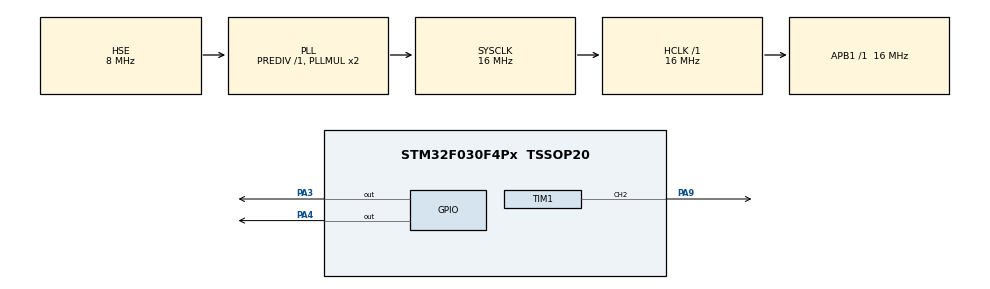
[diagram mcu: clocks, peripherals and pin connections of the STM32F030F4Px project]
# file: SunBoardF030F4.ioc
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Mcu.Family=STM32F0
Mcu.Name=STM32F030F4Px
Mcu.Package=TSSOP20
PA13.Mode=Serial_Wire
PA13.Signal=SYS_SWDIO
PA14.Mode=Serial_Wire
PA14.Signal=SYS_SWCLK
PA3.Signal=GPIO_Output
PA4.Signal=GPIO_Output
PA9.Signal=S_TIM1_CH2
PF0-OSC_IN.Mode=HSE-External-Oscillator
PF0-OSC_IN.Signal=RCC_OSC_IN
PF1-OSC_OUT.Mode=HSE-External-Oscillator
PF1-OSC_OUT.Signal=RCC_OSC_OUT
ProjectManager.HeapSize=0x200
ProjectManager.StackSize=0x400
ProjectManager.TargetToolchain=TrueSTUDIO
RCC.AHBFreq_Value=16000000
RCC.APB1Freq_Value=16000000
RCC.APB1TimFreq_Value=16000000
RCC.HCLKFreq_Value=16000000
RCC.PLLSourceVirtual=RCC_PLLSOURCE_HSE
RCC.RTCClockSelection=RCC_RTCCLKSOURCE_HSE_DIV32
RCC.SYSCLKFreq_VALUE=16000000
RCC.SYSCLKSource=RCC_SYSCLKSOURCE_PLLCLK
RTC.Format=RTC_FORMAT_BIN
RTC.Hours=12
RTC.Minutes=12
RTC.Seconds=12
RTC.SynchPrediv=1999
SH.S_TIM1_CH2.0=TIM1_CH2,PWM Generation2 CH2
TIM1.Channel-PWM\ Generation2\ CH2=TIM_CHANNEL_2
VP_RTC_VS_RTC_Activate.Mode=RTC_Enabled
VP_RTC_VS_RTC_Calendar.Mode=RTC_Calendar
board=custom

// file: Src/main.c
/* USER CODE BEGIN Header */
/**
  ******************************************************************************
  * @file           : main.c
  * @brief          : Main program body
  ******************************************************************************
  ** This notice applies to any and all portions of this file
  * that are not between comment pairs USER CODE BEGIN and
  * USER CODE END. Other portions of this file, whether
  * inserted by the user or by software development tools
  * are owned by their respective copyright owners.
  *
  * COPYRIGHT(c) 2019 STMicroelectronics
  *
  * Redistribution and use in source and binary forms, with or without modification,
  * are permitted provided that the following conditions are met:
  *   1. Redistributions of source code must retain the above copyright notice,
  *      this list of conditions and the following disclaimer.
  *   2. Redistributions in binary form must reproduce the above copyright notice,
  *      this list of conditions and the following disclaimer in the documentation
  *      and/or other materials provided with the distribution.
  *   3. Neither the name of STMicroelectronics nor the names of its contributors
  *      may be used to endorse or promote products derived from this software
  *      without specific prior written permission.
  *
  * THIS SOFTWARE IS PROVIDED BY THE COPYRIGHT HOLDERS AND CONTRIBUTORS "AS IS"
  * AND ANY EXPRESS OR IMPLIED WARRANTIES, INCLUDING, BUT NOT LIMITED TO, THE
  * IMPLIED WARRANTIES OF MERCHANTABILITY AND FITNESS FOR A PARTICULAR PURPOSE ARE
  * DISCLAIMED. IN NO EVENT SHALL THE COPYRIGHT HOLDER OR CONTRIBUTORS BE LIABLE
  * FOR ANY DIRECT, INDIRECT, INCIDENTAL, SPECIAL, EXEMPLARY, OR CONSEQUENTIAL
  * DAMAGES (INCLUDING, BUT NOT LIMITED TO, PROCUREMENT OF SUBSTITUTE GOODS OR
  * SERVICES; LOSS OF USE, DATA, OR PROFITS; OR BUSINESS INTERRUPTION) HOWEVER
  * CAUSED AND ON ANY THEORY OF LIABILITY, WHETHER IN CONTRACT, STRICT LIABILITY,
  * OR TORT (INCLUDING NEGLIGENCE OR OTHERWISE) ARISING IN ANY WAY OUT OF THE USE
  * OF THIS SOFTWARE, EVEN IF ADVISED OF THE POSSIBILITY OF SUCH DAMAGE.
  *
  ******************************************************************************
  */
/* USER CODE END Header */

#include "main.h"

/* USER CODE BEGIN Includes */
#include "pwm.h"
#include "rtc.h"
#include <time.h>
/* USER CODE END Includes */

/* USER CODE BEGIN PTD */
  RTC_TimeTypeDef userTime = {0};
  RTC_DateTypeDef userDate = {0};
/* USER CODE END PTD */

RTC_HandleTypeDef hrtc;

TIM_HandleTypeDef htim1;

void SystemClock_Config(void);
static void MX_GPIO_Init(void);
static void MX_RTC_Init(void);
static void MX_TIM1_Init(void);

int main(void)
{

  /* MCU Configuration--------------------------------------------------------*/

  /* Reset of all peripherals, Initializes the Flash interface and the Systick. */
  HAL_Init();

  /* Configure the system clock */
  SystemClock_Config();

  /* Initialize all configured peripherals */
  MX_GPIO_Init();
  MX_RTC_Init();
  MX_TIM1_Init();
  /* USER CODE BEGIN 2 */
  Set_Current_Time(hrtc); // syncs up RTC with the system clock at compile time.
  uint8_t pwm_flag = 0; // we only want to set the pwm once when the conditions are right, so we use a flag.
  uint8_t prevMin = userTime.Minutes;
  setPWM(htim1,TIM_CHANNEL_2, 255, 200);
  HAL_Delay(1000);
  setPWM(htim1,TIM_CHANNEL_2, 255, 0);
   HAL_Delay(1000);

  for(int i=0; i<256; i++)
  {
	  setPWM(htim1,TIM_CHANNEL_2, 255, i);
	  HAL_Delay(1000);
  }

  /* USER CODE END 2 */

  /* Infinite loop */
  /* USER CODE BEGIN WHILE */
  while (1)
  {
	  // Update date and time.
	  HAL_RTC_GetTime(&hrtc,&userTime,RTC_FORMAT_BIN); // order is specific
	  HAL_RTC_GetDate(&hrtc,&userDate,RTC_FORMAT_BIN);

	  if(userDate.WeekDay==RTC_WEEKDAY_MONDAY){

		  if(userTime.Minutes%2==1){
			  setPWM(htim1,TIM_CHANNEL_2,500,100);
			  HAL_Delay(1000);
		  }
		  else {
			  setPWM(htim1,TIM_CHANNEL_2,500,1);
			  HAL_Delay(1000);
		  }

		  // Yay!
		  if(userTime.Hours==12 && userTime.Minutes==31){

			  //Wakey Wakey dingdong
			  if (pwm_flag==0){
				  setPWM(htim1,TIM_CHANNEL_2,500,100);
				  pwm_flag = 1;
				  HAL_Delay(10); // not sure why the light is so dim...
			  }
			  //HAL_Delay(10);

		  }
		  else{
			  setPWM(htim1,TIM_CHANNEL_2,500,500);
			  uint8_t minutes = userTime.Minutes;
			  minutes = minutes*2;
			  uint8_t hours = userTime.Hours;
			  hours = hours*2;
			  if(hours==minutes){
				  hours = 0;
			  }
			  pwm_flag = 0;
			  HAL_Delay(10);
			  //off_Led();
		  }
	  }

    /* USER CODE END WHILE */

  }
}

void SystemClock_Config(void)
{
  RCC_OscInitTypeDef RCC_OscInitStruct = {0};
  RCC_ClkInitTypeDef RCC_ClkInitStruct = {0};
  RCC_PeriphCLKInitTypeDef PeriphClkInit = {0};

  /**Initializes the CPU, AHB and APB busses clocks
  */
  RCC_OscInitStruct.OscillatorType = RCC_OSCILLATORTYPE_HSE;
  RCC_OscInitStruct.HSEState = RCC_HSE_ON;
  RCC_OscInitStruct.PLL.PLLState = RCC_PLL_ON;
  RCC_OscInitStruct.PLL.PLLSource = RCC_PLLSOURCE_HSE;
  RCC_OscInitStruct.PLL.PLLMUL = RCC_PLL_MUL2;
  RCC_OscInitStruct.PLL.PREDIV = RCC_PREDIV_DIV1;
  if (HAL_RCC_OscConfig(&RCC_OscInitStruct) != HAL_OK)
  {
    Error_Handler();
  }
  /**Initializes the CPU, AHB and APB busses clocks
  */
  RCC_ClkInitStruct.ClockType = RCC_CLOCKTYPE_HCLK|RCC_CLOCKTYPE_SYSCLK
                              |RCC_CLOCKTYPE_PCLK1;
  RCC_ClkInitStruct.SYSCLKSource = RCC_SYSCLKSOURCE_PLLCLK;
  RCC_ClkInitStruct.AHBCLKDivider = RCC_SYSCLK_DIV1;
  RCC_ClkInitStruct.APB1CLKDivider = RCC_HCLK_DIV1;

  if (HAL_RCC_ClockConfig(&RCC_ClkInitStruct, FLASH_LATENCY_0) != HAL_OK)
  {
    Error_Handler();
  }
  PeriphClkInit.PeriphClockSelection = RCC_PERIPHCLK_RTC;
  PeriphClkInit.RTCClockSelection = RCC_RTCCLKSOURCE_HSE_DIV32;
  if (HAL_RCCEx_PeriphCLKConfig(&PeriphClkInit) != HAL_OK)
  {
    Error_Handler();
  }
}

static void MX_RTC_Init(void)
{

  RTC_TimeTypeDef sTime = {0};
  RTC_DateTypeDef sDate = {0};

  /**Initialize RTC Only
  */
  hrtc.Instance = RTC;
  hrtc.Init.HourFormat = RTC_HOURFORMAT_24;
  hrtc.Init.AsynchPrediv = 127;
  hrtc.Init.SynchPrediv = 1999;
  hrtc.Init.OutPut = RTC_OUTPUT_DISABLE;
  hrtc.Init.OutPutPolarity = RTC_OUTPUT_POLARITY_HIGH;
  hrtc.Init.OutPutType = RTC_OUTPUT_TYPE_OPENDRAIN;
  if (HAL_RTC_Init(&hrtc) != HAL_OK)
  {
    Error_Handler();
  }

  /**Initialize RTC and set the Time and Date
  */
  sTime.Hours = 12;
  sTime.Minutes = 12;
  sTime.Seconds = 12;
  sTime.DayLightSaving = RTC_DAYLIGHTSAVING_NONE;
  sTime.StoreOperation = RTC_STOREOPERATION_RESET;
  if (HAL_RTC_SetTime(&hrtc, &sTime, RTC_FORMAT_BIN) != HAL_OK)
  {
    Error_Handler();
  }
  sDate.WeekDay = RTC_WEEKDAY_MONDAY;
  sDate.Month = RTC_MONTH_JANUARY;
  sDate.Date = 1;
  sDate.Year = 0;

  if (HAL_RTC_SetDate(&hrtc, &sDate, RTC_FORMAT_BIN) != HAL_OK)
  {
    Error_Handler();
  }

}

static void MX_TIM1_Init(void)
{

  TIM_MasterConfigTypeDef sMasterConfig = {0};
  TIM_OC_InitTypeDef sConfigOC = {0};
  TIM_BreakDeadTimeConfigTypeDef sBreakDeadTimeConfig = {0};

  htim1.Instance = TIM1;
  htim1.Init.Prescaler = 0;
  htim1.Init.CounterMode = TIM_COUNTERMODE_UP;
  htim1.Init.Period = 0;
  htim1.Init.ClockDivision = TIM_CLOCKDIVISION_DIV1;
  htim1.Init.RepetitionCounter = 0;
  htim1.Init.AutoReloadPreload = TIM_AUTORELOAD_PRELOAD_DISABLE;
  if (HAL_TIM_PWM_Init(&htim1) != HAL_OK)
  {
    Error_Handler();
  }
  sMasterConfig.MasterOutputTrigger = TIM_TRGO_RESET;
  sMasterConfig.MasterSlaveMode = TIM_MASTERSLAVEMODE_DISABLE;
  if (HAL_TIMEx_MasterConfigSynchronization(&htim1, &sMasterConfig) != HAL_OK)
  {
    Error_Handler();
  }
  sConfigOC.OCMode = TIM_OCMODE_PWM1;
  sConfigOC.Pulse = 0;
  sConfigOC.OCPolarity = TIM_OCPOLARITY_HIGH;
  sConfigOC.OCNPolarity = TIM_OCNPOLARITY_HIGH;
  sConfigOC.OCFastMode = TIM_OCFAST_DISABLE;
  sConfigOC.OCIdleState = TIM_OCIDLESTATE_RESET;
  sConfigOC.OCNIdleState = TIM_OCNIDLESTATE_RESET;
  if (HAL_TIM_PWM_ConfigChannel(&htim1, &sConfigOC, TIM_CHANNEL_2) != HAL_OK)
  {
    Error_Handler();
  }
  sBreakDeadTimeConfig.OffStateRunMode = TIM_OSSR_DISABLE;
  sBreakDeadTimeConfig.OffStateIDLEMode = TIM_OSSI_DISABLE;
  sBreakDeadTimeConfig.LockLevel = TIM_LOCKLEVEL_OFF;
  sBreakDeadTimeConfig.DeadTime = 0;
  sBreakDeadTimeConfig.BreakState = TIM_BREAK_DISABLE;
  sBreakDeadTimeConfig.BreakPolarity = TIM_BREAKPOLARITY_HIGH;
  sBreakDeadTimeConfig.AutomaticOutput = TIM_AUTOMATICOUTPUT_DISABLE;
  if (HAL_TIMEx_ConfigBreakDeadTime(&htim1, &sBreakDeadTimeConfig) != HAL_OK)
  {
    Error_Handler();
  }
  HAL_TIM_MspPostInit(&htim1);

}

static void MX_GPIO_Init(void)
{
  GPIO_InitTypeDef GPIO_InitStruct = {0};

  /* GPIO Ports Clock Enable */
  __HAL_RCC_GPIOF_CLK_ENABLE();
  __HAL_RCC_GPIOA_CLK_ENABLE();

  /*Configure GPIO pin Output Level */
  HAL_GPIO_WritePin(GPIOA, GPIO_PIN_3|GPIO_PIN_4, GPIO_PIN_RESET);

  /*Configure GPIO pins : PA3 PA4 */
  GPIO_InitStruct.Pin = GPIO_PIN_3|GPIO_PIN_4;
  GPIO_InitStruct.Mode = GPIO_MODE_OUTPUT_PP;
  GPIO_InitStruct.Pull = GPIO_NOPULL;
  GPIO_InitStruct.Speed = GPIO_SPEED_FREQ_LOW;
  HAL_GPIO_Init(GPIOA, &GPIO_InitStruct);

}

void Error_Handler(void)
{
}

/************************ (C) COPYRIGHT STMicroelectronics *****END OF FILE****/
